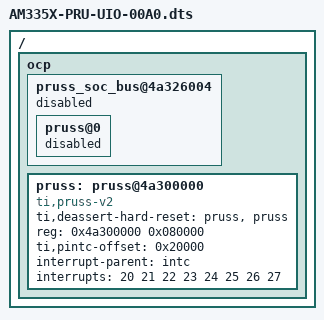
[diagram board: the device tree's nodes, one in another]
/*
 * Copyright (C) 2012 Texas Instruments Incorporated - http://www.ti.com/
 *
 * This program is free software; you can redistribute it and/or modify
 * it under the terms of the GNU General Public License version 2 as
 * published by the Free Software Foundation.
 */

/dts-v1/;
/plugin/;

/ {
	fragment@0 {
		target-path="/";
		__overlay__ {

			ocp {
				#address-cells = <1>;
				#size-cells = <1>;

				//v4.14.x-ti
				pruss_soc_bus@4a326004 {
					status = "disabled";

					//v4.14.x-ti
					pruss@0 {
						status = "disabled";
					};
				};

				pruss: pruss@4a300000 {
					status = "okay";
					compatible = "ti,pruss-v2";
					ti,deassert-hard-reset = "pruss", "pruss";
					reg = <0x4a300000 0x080000>;
					ti,pintc-offset = <0x20000>;
					interrupt-parent = <&intc>;
					interrupts = <20 21 22 23 24 25 26 27>;
				};
			};
		};
	};
};
